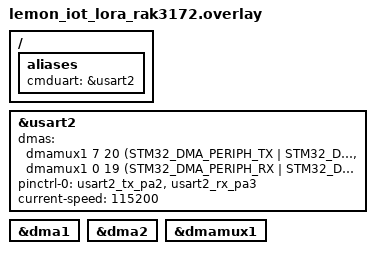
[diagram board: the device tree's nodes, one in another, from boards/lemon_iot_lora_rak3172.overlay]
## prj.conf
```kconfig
CONFIG_CONSOLE=y
CONFIG_SERIAL=y
CONFIG_DMA=y
CONFIG_DMA_STM32=y
CONFIG_UART_ASYNC_API=y
```

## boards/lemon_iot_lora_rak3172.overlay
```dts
/ {
	aliases {
		cmduart = &usart2;
	};
};

&usart2 {
	// Binding information for STM32 DMAMUX Controller
	// https://docs.zephyrproject.org/3.0.0/reference/devicetree/bindings/dma/st%2Cstm32-dmamux.html#dtbinding-st-stm32-dmamux

	// STM32_DMA.h File Reference
	// https://docs.zephyrproject.org/apidoc/latest/stm32__dma_8h.html

	// DMA1 controller has 7 Channels, DMA2 controller another 7 Channels
	// DMAMUX1 channels 0 to 6 are connected to DMA1 channels 1 to 7
	// DMAMUX1 channels 7 to 13 are connected to DMA2 channels 1 to 7

	// Slot 17 = USART1_RX, Slot 18 = USART1_TX
	// Slot 19 = USART2_RX, Slot 20 = USART2_TX
	// Slot 21 = LPUART1_RX, Slot 22 = LPUART1_TX

	// Format of DMA cell below: Channel, slot, channel configuration

	dmas = <&dmamux1 7 20 (STM32_DMA_PERIPH_TX | STM32_DMA_PRIORITY_MEDIUM)
		   &dmamux1 0 19 (STM32_DMA_PERIPH_RX | STM32_DMA_PRIORITY_MEDIUM)>;
	dma-names = "TX", "RX";
	pinctrl-0 = <&usart2_tx_pa2 &usart2_rx_pa3>;
	pinctrl-names = "default";
	current-speed = <115200>;
	status = "okay";
};

&dma1 {
	status = "okay";
};

&dma2 {
	status = "okay";
};

&dmamux1 {
	status = "okay";
};
```

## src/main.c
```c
/*
 *  Copyright (c) 2019 Nordic Semiconductor ASA
 *
 * SPDX-License-Identifier: Apache-2.0
 */

#include <stdio.h>
#include <string.h>
#include <zephyr/device.h>
#include <zephyr/kernel.h>
#include <zephyr/drivers/uart.h>

#define BUF_SIZE 64

static K_MEM_SLAB_DEFINE(uart_slab, BUF_SIZE, 3, 4);

K_SEM_DEFINE(uart_rx_rdy_sem, 0, 1);
uint8_t *read_ptr;
size_t read_len;

void uart_callback(const struct device *dev, struct uart_event *evt, void *user_data)
{

	switch (evt->type) {
	
		case UART_TX_DONE:
			printk("TX Done %d bytes\n", evt->data.tx.len);
			break;
	
		case UART_TX_ABORTED:
			break;
	
		case UART_RX_RDY:
			read_ptr = evt->data.rx.buf + evt->data.rx.offset;
			read_len = evt->data.rx.len;
			k_sem_give(&uart_rx_rdy_sem);
			break;

		case UART_RX_BUF_REQUEST:
		{
			int ret;
			uint8_t *buf;

			ret = k_mem_slab_alloc(&uart_slab, (void **)&buf, K_NO_WAIT);
			if (ret != 0) {
				printk("Failed to allocate slab\n");
			}

			ret = uart_rx_buf_rsp(dev, buf, BUF_SIZE);
			if (ret != 0) {
				printk("Failed to provide new buffer\n");
			}
			break;
		}
	
		case UART_RX_BUF_RELEASED:
			k_mem_slab_free(&uart_slab, (void **)&evt->data.rx_buf.buf);
			break;
	
		case UART_RX_DISABLED:
			printk("RX Disabled\n");
			break;
	
		default:
			break;
	}
}

int main(void)
{
	const struct device *uart_dev;
	char buffer[100];
	uint8_t *buf;
	int ret;

	printk("UART Example\nBoard: %s\n", CONFIG_BOARD);

	uart_dev = DEVICE_DT_GET(DT_ALIAS(cmduart));
	if (!uart_dev) {
		printk("uartlog DT alias not found.\n");
		return(-1);
	}

	if (!device_is_ready(uart_dev)) {
		printk("UART device not ready.\n");
		return(-1);
	}
 
	ret = k_mem_slab_alloc(&uart_slab, (void **)&buf, K_NO_WAIT);
	if (ret != 0) {
		printk("k_mem_slab_alloc() error (%d)\n", ret);
		return(-1);
	}

	ret = uart_callback_set(uart_dev, uart_callback, NULL);
	if (ret != 0) {
		printk("uart_callback_set() error (%d)\n", ret);
		if (ret == -ENOTSUP) printk("ASYNC API not enabled\n");
		return(-1);
	}

	ret = uart_rx_enable(uart_dev, buf, BUF_SIZE, 100000);
	if ((ret != 0) & (ret != -EBUSY)) {
		printk("uart_rx_enable() error (%d)\n", ret);
	}

	sprintf(buffer, "Hello World\r\n");
	ret = uart_tx(uart_dev, buffer, strlen(buffer), 0);
	if (ret != 0 ) {
		printk("uart_tx() error (%d)\n", ret);
	}

	do {

		if (k_sem_take(&uart_rx_rdy_sem, K_NO_WAIT) != 0) {
			//printk("k_sem_take error\n");
		} else {
			//printk("RX %d bytes: ", read_len);
			
			for (int i = 0; i < read_len; i++) {
				if (*(read_ptr + i) == 0x0D) {
					printk("\n");
				} else {
					printk("%c", *(read_ptr + i) );
				}
			}
		}

	} while(1);
}
```
